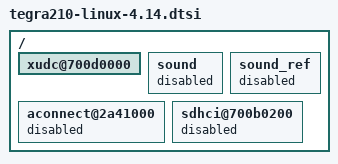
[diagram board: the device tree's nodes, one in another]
/*
 * tegra210-linux-4.14.dtsi
 *
 * Copyright (c) 2018, NVIDIA CORPORATION.  All rights reserved.
 *
 * This program is free software; you can redistribute it and/or modify
 * it under the terms of the GNU General Public License as published by
 * the Free Software Foundation; version 2 of the License.
 *
 * This program is distributed in the hope that it will be useful, but WITHOUT
 * ANY WARRANTY; without even the implied warranty of MERCHANTABILITY or
 * FITNESS FOR A PARTICULAR PURPOSE.  See the GNU General Public License for
 * more details.
 */

/ {
	xudc@700d0000 {
		/delete-property/ iommus;
	};

	sound {
		status = "disabled";
	};

	sound_ref {
		status = "disabled";
	};

	aconnect@2a41000 {
		status = "disabled";
	};

	sdhci@700b0200 {
		status = "disabled";
	};
};
